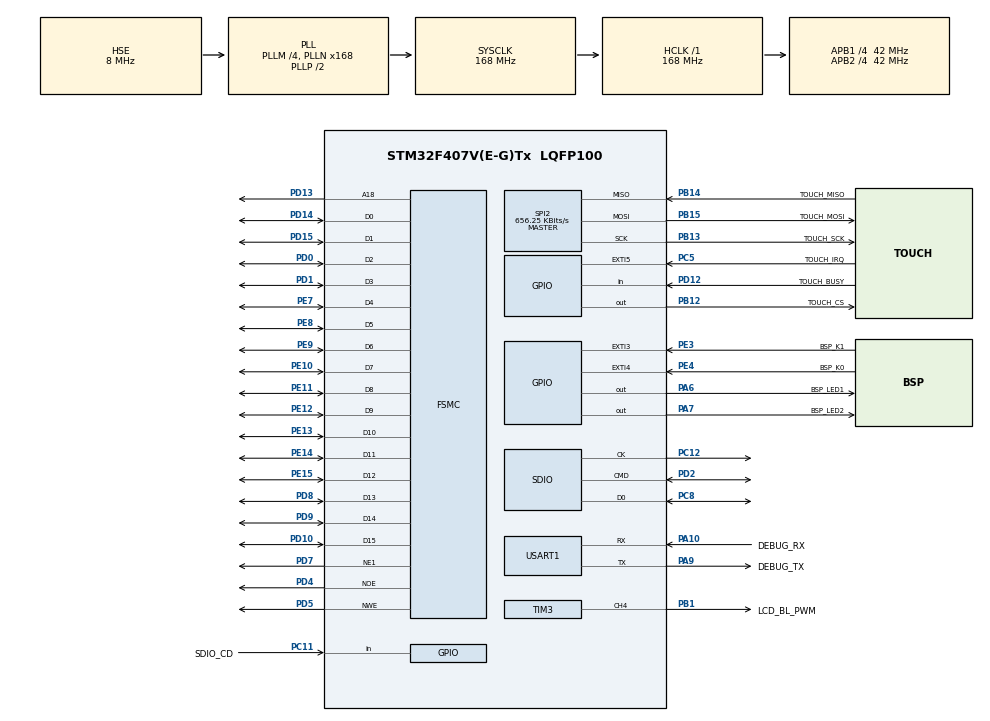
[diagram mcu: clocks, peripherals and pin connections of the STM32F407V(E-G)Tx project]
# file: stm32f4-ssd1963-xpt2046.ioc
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FATFS.BSP.number=1
FATFS0.BSP.STBoard=false
FATFS0.BSP.api=UnknownBspDriver
FATFS0.BSP.i2caddr=0
FATFS0.BSP.i2creg=0
FATFS0.BSP.instance=PC11
FATFS0.BSP.ip=GPIO
FATFS0.BSP.mode=Input
FATFS0.BSP.name=Detect_SDIO
FATFS0.BSP.solution=PC11
FSMC.AddressSetupTime1=1
FSMC.BusTurnAroundDuration1=1
FSMC.DataSetupTime1=2
Mcu.Family=STM32F4
Mcu.Name=STM32F407V(E-G)Tx
Mcu.Package=LQFP100
NVIC.EXTI3_IRQn=true\:0\:0\:false\:false\:true\:true
NVIC.EXTI4_IRQn=true\:0\:0\:false\:false\:true\:true
NVIC.EXTI9_5_IRQn=true\:0\:0\:false\:false\:true\:true
NVIC.PriorityGroup=NVIC_PRIORITYGROUP_4
NVIC.TIM3_IRQn=true\:0\:0\:false\:false\:true\:true
NVIC.TIM6_DAC_IRQn=true\:0\:0\:false\:false\:true\:true
NVIC.TIM7_IRQn=true\:0\:0\:false\:false\:true\:true
NVIC.USART1_IRQn=true\:0\:0\:false\:false\:true\:true
PA10.GPIO_Label=DEBUG_RX
PA10.Mode=Asynchronous
PA10.Signal=USART1_RX
PA13.Mode=Serial_Wire
PA13.Signal=SYS_JTMS-SWDIO
PA14.Mode=Serial_Wire
PA14.Signal=SYS_JTCK-SWCLK
PA6.GPIO_Label=BSP_LED1
PA6.Signal=GPIO_Output
PA7.GPIO_Label=BSP_LED2
PA7.Signal=GPIO_Output
PA9.GPIO_Label=DEBUG_TX
PA9.Mode=Asynchronous
PA9.Signal=USART1_TX
PB1.GPIO_Label=LCD_BL_PWM
PB1.Signal=S_TIM3_CH4
PB12.GPIO_Label=TOUCH_CS
PB12.Signal=GPIO_Output
PB13.GPIO_Label=TOUCH_SCK
PB13.Mode=Full_Duplex_Master
PB13.Signal=SPI2_SCK
PB14.GPIO_Label=TOUCH_MISO
PB14.Mode=Full_Duplex_Master
PB14.Signal=SPI2_MISO
PB15.GPIO_Label=TOUCH_MOSI
PB15.Mode=Full_Duplex_Master
PB15.Signal=SPI2_MOSI
PC11.GPIO_Label=SDIO_CD
PC11.Signal=GPIO_Input
PC12.Mode=SD_1_bit
PC12.Signal=SDIO_CK
PC14-OSC32_IN.Mode=LSE-External-Oscillator
PC14-OSC32_IN.Signal=RCC_OSC32_IN
PC15-OSC32_OUT.Mode=LSE-External-Oscillator
PC15-OSC32_OUT.Signal=RCC_OSC32_OUT
PC5.GPIO_Label=TOUCH_IRQ
PC5.Signal=GPXTI5
PC8.Mode=SD_1_bit
PC8.Signal=SDIO_D0
PD0.Mode=16b-d1
PD0.Signal=FSMC_D2
PD1.Mode=16b-d1
PD1.Signal=FSMC_D3
PD10.Mode=16b-d1
PD10.Signal=FSMC_D15
PD12.GPIO_Label=TOUCH_BUSY
PD12.Signal=GPIO_Input
PD13.Mode=A18_1
PD13.Signal=FSMC_A18
PD14.Mode=16b-d1
PD14.Signal=FSMC_D0
PD15.Mode=16b-d1
PD15.Signal=FSMC_D1
PD2.Mode=SD_1_bit
PD2.Signal=SDIO_CMD
PD4.Mode=Lcd1
PD4.Signal=FSMC_NOE
PD5.Mode=Lcd1
PD5.Signal=FSMC_NWE
PD7.Mode=NorPsramChipSelect1_1
PD7.Signal=FSMC_NE1
PD8.Mode=16b-d1
PD8.Signal=FSMC_D13
PD9.Mode=16b-d1
PD9.Signal=FSMC_D14
PE10.Mode=16b-d1
PE10.Signal=FSMC_D7
PE11.Mode=16b-d1
PE11.Signal=FSMC_D8
PE12.Mode=16b-d1
PE12.Signal=FSMC_D9
PE13.Mode=16b-d1
PE13.Signal=FSMC_D10
PE14.Mode=16b-d1
PE14.Signal=FSMC_D11
PE15.Mode=16b-d1
PE15.Signal=FSMC_D12
PE3.GPIO_Label=BSP_K1
PE3.Signal=GPXTI3
PE4.GPIO_Label=BSP_K0
PE4.Signal=GPXTI4
PE7.Mode=16b-d1
PE7.Signal=FSMC_D4
PE8.Mode=16b-d1
PE8.Signal=FSMC_D5
PE9.Mode=16b-d1
PE9.Signal=FSMC_D6
PH0-OSC_IN.Mode=HSE-External-Oscillator
PH0-OSC_IN.Signal=RCC_OSC_IN
PH1-OSC_OUT.Mode=HSE-External-Oscillator
PH1-OSC_OUT.Signal=RCC_OSC_OUT
ProjectManager.HeapSize=0x200
ProjectManager.StackSize=0x400
ProjectManager.TargetToolchain=Makefile
RCC.48MHZClocksFreq_Value=48000000
RCC.AHBFreq_Value=168000000
RCC.APB1CLKDivider=RCC_HCLK_DIV4
RCC.APB1Freq_Value=42000000
RCC.APB1TimFreq_Value=84000000
RCC.APB2CLKDivider=RCC_HCLK_DIV4
RCC.APB2Freq_Value=42000000
RCC.APB2TimFreq_Value=84000000
RCC.CortexFreq_Value=168000000
RCC.HCLKFreq_Value=168000000
RCC.HSE_VALUE=8000000
RCC.HSI_VALUE=16000000
RCC.PLLM=4
RCC.PLLN=168
RCC.PLLQ=7
RCC.PLLSourceVirtual=RCC_PLLSOURCE_HSE
RCC.RCC_RTC_Clock_Source=RCC_RTCCLKSOURCE_LSE
RCC.RCC_RTC_Clock_SourceVirtual=RCC_RTCCLKSOURCE_LSE
RCC.SYSCLKFreq_VALUE=168000000
RCC.SYSCLKSource=RCC_SYSCLKSOURCE_PLLCLK
RCC.VCOOutputFreq_Value=336000000
SH.S_TIM3_CH4.0=TIM3_CH4,PWM Generation4 CH4
SPI2.BaudRatePrescaler=SPI_BAUDRATEPRESCALER_64
SPI2.CalculateBaudRate=656.25 KBits/s
SPI2.Direction=SPI_DIRECTION_2LINES
SPI2.Mode=SPI_MODE_MASTER
SPI2.VirtualType=VM_MASTER
TIM3.Channel-PWM\ Generation4\ CH4=TIM_CHANNEL_4
TIM3.Period=100-1
TIM3.Prescaler=1680-1
TIM6.Period=500-1
TIM6.Prescaler=8400-1
TIM7.Period=100-1
TIM7.Prescaler=840-1
USART1.VirtualMode=VM_ASYNC
VP_FATFS_VS_SDIO.Mode=SDIO
VP_RTC_VS_RTC_Activate.Mode=RTC_Enabled
VP_TIM3_VS_ClockSourceINT.Mode=Internal
VP_TIM6_VS_ClockSourceINT.Mode=Enable_Timer
VP_TIM7_VS_ClockSourceINT.Mode=Enable_Timer
board=stm32f4-ssd1963-xpt2046

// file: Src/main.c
/**
  ******************************************************************************
  * @file           : main.c
  * @brief          : Main program body
  ******************************************************************************
  * This notice applies to any and all portions of this file
  * that are not between comment pairs USER CODE BEGIN and
  * USER CODE END. Other portions of this file, whether
  * inserted by the user or by software development tools
  * are owned by their respective copyright owners.
  *
  * Copyright (c) 2018 STMicroelectronics International N.V.
  * All rights reserved.
  *
  * Redistribution and use in source and binary forms, with or without
  * modification, are permitted, provided that the following conditions are met:
  *
  * 1. Redistribution of source code must retain the above copyright notice,
  *    this list of conditions and the following disclaimer.
  * 2. Redistributions in binary form must reproduce the above copyright notice,
  *    this list of conditions and the following disclaimer in the documentation
  *    and/or other materials provided with the distribution.
  * 3. Neither the name of STMicroelectronics nor the names of other
  *    contributors to this software may be used to endorse or promote products
  *    derived from this software without specific written permission.
  * 4. This software, including modifications and/or derivative works of this
  *    software, must execute solely and exclusively on microcontroller or
  *    microprocessor devices manufactured by or for STMicroelectronics.
  * 5. Redistribution and use of this software other than as permitted under
  *    this license is void and will automatically terminate your rights under
  *    this license.
  *
  * THIS SOFTWARE IS PROVIDED BY STMICROELECTRONICS AND CONTRIBUTORS "AS IS"
  * AND ANY EXPRESS, IMPLIED OR STATUTORY WARRANTIES, INCLUDING, BUT NOT
  * LIMITED TO, THE IMPLIED WARRANTIES OF MERCHANTABILITY, FITNESS FOR A
  * PARTICULAR PURPOSE AND NON-INFRINGEMENT OF THIRD PARTY INTELLECTUAL PROPERTY
  * RIGHTS ARE DISCLAIMED TO THE FULLEST EXTENT PERMITTED BY LAW. IN NO EVENT
  * SHALL STMICROELECTRONICS OR CONTRIBUTORS BE LIABLE FOR ANY DIRECT, INDIRECT,
  * INCIDENTAL, SPECIAL, EXEMPLARY, OR CONSEQUENTIAL DAMAGES (INCLUDING, BUT NOT
  * LIMITED TO, PROCUREMENT OF SUBSTITUTE GOODS OR SERVICES; LOSS OF USE, DATA,
  * OR PROFITS; OR BUSINESS INTERRUPTION) HOWEVER CAUSED AND ON ANY THEORY OF
  * LIABILITY, WHETHER IN CONTRACT, STRICT LIABILITY, OR TORT (INCLUDING
  * NEGLIGENCE OR OTHERWISE) ARISING IN ANY WAY OUT OF THE USE OF THIS SOFTWARE,
  * EVEN IF ADVISED OF THE POSSIBILITY OF SUCH DAMAGE.
  *
  ******************************************************************************
  */
#include "main.h"
#include "stm32f4xx_hal.h"
#include "fatfs.h"
#include "rtc.h"
#include "sdio.h"
#include "spi.h"
#include "tim.h"
#include "usart.h"
#include "gpio.h"
#include "fsmc.h"

/* USER CODE BEGIN Includes */
#include "uart_printf.h"

/* USER CODE END Includes */

/* USER CODE BEGIN PV */
/* Private variables ---------------------------------------------------------*/

/* USER CODE END PV */

void SystemClock_Config(void);

/* USER CODE BEGIN PFP */
/* Private function prototypes -----------------------------------------------*/

/* USER CODE END PFP */

int main(void)
{

  /* MCU Configuration----------------------------------------------------------*/

  /* Reset of all peripherals, Initializes the Flash interface and the Systick. */
  HAL_Init();

  /* Configure the system clock */
  SystemClock_Config();

  /* Initialize all configured peripherals */
  MX_GPIO_Init();
  MX_FSMC_Init();
  MX_RTC_Init();
  MX_SDIO_SD_Init();
  MX_SPI2_Init();
  MX_TIM3_Init();
  MX_TIM6_Init();
  MX_TIM7_Init();
  MX_USART1_UART_Init();
  MX_FATFS_Init();
  /* USER CODE BEGIN 2 */

  printf("Application begin...\n\r");

  /* USER CODE END 2 */

  /* Infinite loop */
  while (1)
  {

  }

}

void SystemClock_Config(void)
{

  RCC_OscInitTypeDef RCC_OscInitStruct;
  RCC_ClkInitTypeDef RCC_ClkInitStruct;
  RCC_PeriphCLKInitTypeDef PeriphClkInitStruct;

    /**Configure the main internal regulator output voltage
    */
  __HAL_RCC_PWR_CLK_ENABLE();

  __HAL_PWR_VOLTAGESCALING_CONFIG(PWR_REGULATOR_VOLTAGE_SCALE1);

    /**Initializes the CPU, AHB and APB busses clocks
    */
  RCC_OscInitStruct.OscillatorType = RCC_OSCILLATORTYPE_HSE|RCC_OSCILLATORTYPE_LSE;
  RCC_OscInitStruct.HSEState = RCC_HSE_ON;
  RCC_OscInitStruct.LSEState = RCC_LSE_ON;
  RCC_OscInitStruct.PLL.PLLState = RCC_PLL_ON;
  RCC_OscInitStruct.PLL.PLLSource = RCC_PLLSOURCE_HSE;
  RCC_OscInitStruct.PLL.PLLM = 4;
  RCC_OscInitStruct.PLL.PLLN = 168;
  RCC_OscInitStruct.PLL.PLLP = RCC_PLLP_DIV2;
  RCC_OscInitStruct.PLL.PLLQ = 7;
  if (HAL_RCC_OscConfig(&RCC_OscInitStruct) != HAL_OK)
  {
    _Error_Handler(__FILE__, __LINE__);
  }

    /**Initializes the CPU, AHB and APB busses clocks
    */
  RCC_ClkInitStruct.ClockType = RCC_CLOCKTYPE_HCLK|RCC_CLOCKTYPE_SYSCLK
                              |RCC_CLOCKTYPE_PCLK1|RCC_CLOCKTYPE_PCLK2;
  RCC_ClkInitStruct.SYSCLKSource = RCC_SYSCLKSOURCE_PLLCLK;
  RCC_ClkInitStruct.AHBCLKDivider = RCC_SYSCLK_DIV1;
  RCC_ClkInitStruct.APB1CLKDivider = RCC_HCLK_DIV4;
  RCC_ClkInitStruct.APB2CLKDivider = RCC_HCLK_DIV4;

  if (HAL_RCC_ClockConfig(&RCC_ClkInitStruct, FLASH_LATENCY_5) != HAL_OK)
  {
    _Error_Handler(__FILE__, __LINE__);
  }

  PeriphClkInitStruct.PeriphClockSelection = RCC_PERIPHCLK_RTC;
  PeriphClkInitStruct.RTCClockSelection = RCC_RTCCLKSOURCE_LSE;
  if (HAL_RCCEx_PeriphCLKConfig(&PeriphClkInitStruct) != HAL_OK)
  {
    _Error_Handler(__FILE__, __LINE__);
  }

    /**Configure the Systick interrupt time
    */
  HAL_SYSTICK_Config(HAL_RCC_GetHCLKFreq()/1000);

    /**Configure the Systick
    */
  HAL_SYSTICK_CLKSourceConfig(SYSTICK_CLKSOURCE_HCLK);

  /* SysTick_IRQn interrupt configuration */
  HAL_NVIC_SetPriority(SysTick_IRQn, 0, 0);
}

void _Error_Handler(char *file, int line)
{
  while(1)
  {
  }
}

/************************ (C) COPYRIGHT STMicroelectronics *****END OF FILE****/
